AUTOSAR XML (schema 00051)
package /ComponentTypes
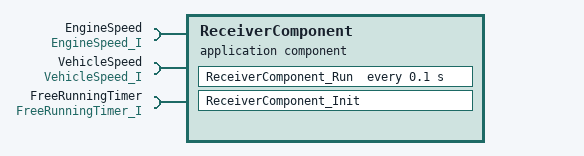
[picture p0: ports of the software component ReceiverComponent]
  application sw component type ReceiverComponent
    require port EngineSpeed: nonqueued-receiver-com-spec{data-element=EngineSpeed, init-value=constant-reference=EngineSpeed_IV}, required-interface=EngineSpeed_I
    require port VehicleSpeed: nonqueued-receiver-com-spec{data-element=VehicleSpeed, init-value=constant-reference=VehicleSpeed_IV}, required-interface=VehicleSpeed_I
    require port FreeRunningTimer: required-com-specs=[GetTime, IsTimerElapsed], required-interface=FreeRunningTimer_I
    behavior ReceiverComponent_InternalBehavior
      init event IT_ReceiverComponent_Init: start-on-event=ReceiverComponent_Init
      timing event TMT_ReceiverComponent_Run: start-on-event=ReceiverComponent_Run, period=0.1
      runnable ReceiverComponent_Init
      runnable ReceiverComponent_Run
  swc implementation ReceiverComponent_Implementation: behavior=ReceiverComponent_InternalBehavior
